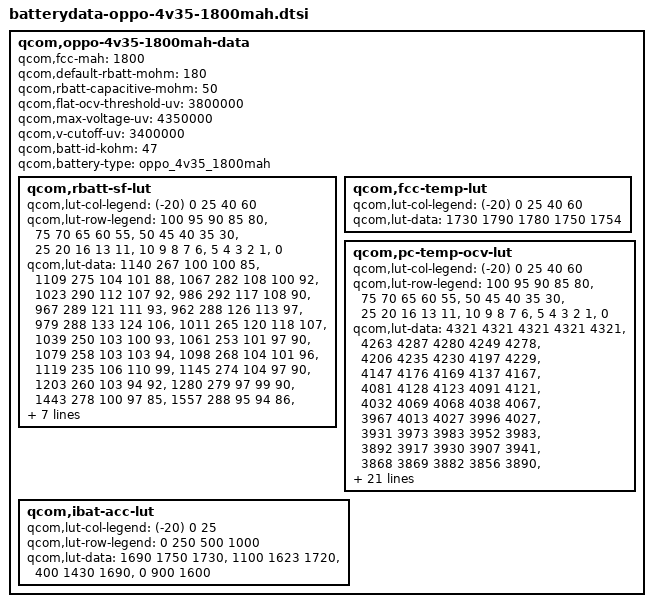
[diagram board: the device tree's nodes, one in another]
/* Copyright (c) 2013, The Linux Foundation. All rights reserved.
 *
 * This program is free software; you can redistribute it and/or modify
 * it under the terms of the GNU General Public License version 2 and
 * only version 2 as published by the Free Software Foundation.
 *
 * This program is distributed in the hope that it will be useful,
 * but WITHOUT ANY WARRANTY; without even the implied warranty of
 * MERCHANTABILITY or FITNESS FOR A PARTICULAR PURPOSE.  See the
 * GNU General Public License for more details.
 */

qcom,oppo-4v35-1800mah-data {
	qcom,fcc-mah = <1800>;
	qcom,default-rbatt-mohm = <180>;
	qcom,rbatt-capacitive-mohm = <50>;
	qcom,flat-ocv-threshold-uv = <3800000>;
	qcom,max-voltage-uv = <4350000>;
	qcom,v-cutoff-uv = <3400000>;
	//qcom,chg-term-ua = <100000>;
	qcom,batt-id-kohm = <47>;
	qcom,battery-type = "oppo_4v35_1800mah";

	qcom,rbatt-sf-lut {
		qcom,lut-col-legend = <(-20) 0 25 40 60>;
		qcom,lut-row-legend = <100 95 90 85 80>,
				<75 70 65 60 55>,
				<50 45 40 35 30>,
				<25 20 16 13 11>,
				<10 9 8 7 6>,
				<5 4 3 2 1>,
				<0>;
		qcom,lut-data = <1140 267 100 100 85>,
			   	<1109 275 104 101 88>,
			   	<1067 282 108 100 92>,
			   	<1023 290 112 107 92>,
			   	<986 292 117 108 90>,
			   	<967 289 121 111 93>,
			   	<962 288 126 113 97>,
			   	<979 288 133 124 106>,
			   	<1011 265 120 118 107>,
			   	<1039 250 103 100 93>,
			   	<1061 253 101 97 90>,
			   	<1079 258 103 103 94>,
			   	<1098 268 104 101 96>,
			   	<1119 235 106 110 99>,
			   	<1145 274 104 97 90>,
			   	<1203 260 103 94 92>,
			   	<1280 279 97 99 90>,
			   	<1443 278 100 97 85>,
			   	<1557 288 95 94 86>,
			   	<1661 288 96 99 96>,
			   	<1772 297 100 106 97>,
			   	<1828 303 106 104 97>,
			   	<1883 318 110 114 103>,
			   	<1939 343 115 108 101>,
			   	<1994 382 113 110 97>,
			   	<2000 439 111 110 100>,	
			   	<2106 535 121 113 105>,
			   	<2217 754 135 125 117>,
			  	<2772 1135 171 149 151>,
			   	<5550 1383 858 571 651>,
			   	<135251 124940 59087 49820 29672>;
	};

	qcom,fcc-temp-lut {
		qcom,lut-col-legend = <(-20) 0 25 40 60>;
		qcom,lut-data = <1730 1790 1780 1750 1754>;
	};

	qcom,pc-temp-ocv-lut {
		qcom,lut-col-legend = <(-20) 0 25 40 60>;
		qcom,lut-row-legend = <100 95 90 85 80>,
				<75 70 65 60 55>,
				<50 45 40 35 30>,
				<25 20 16 13 11>,
				<10 9 8 7 6>,
				<5 4 3 2 1>,
				<0>;
		//qcom,lut-data = <4342 4350 4341 4311 4337>,
		qcom,lut-data = <4321 4321 4321 4321 4321>,
			   	<4263 4287 4280 4249 4278>,
			   	<4206 4235 4230 4197 4229>,
			   	<4147 4176 4169 4137 4167>,
			   	<4081 4128 4123 4091 4121>,
			   	<4032 4069 4068 4038 4067>,
			   	<3967 4013 4027 3996 4027>,
			   	<3931 3973 3983 3952 3983>,
			   	<3892 3917 3930 3907 3941>,
			   	<3868 3869 3882 3856 3890>,
			   	<3837 3844 3850 3828 3865>,
			   	<3816 3820 3830 3806 3840>,
			   	<3798 3802 3810 3785 3824>,
			   	<3776 3790 3797 3775 3806>,
			   	<3760 3777 3781 3751 3782>,
			   	<3740 3770 3761 3730 3740>,
			   	<3725 3751 3742 3710 3710>,
			   	<3696 3712 3706 3699 3687>,
			   	<3663 3699 3691 3680 3671>,
			   	<3620 3663 3674 3672 3662>,
			   	<3601 3656 3671 3669 3659>,
			  	<3580 3649 3667 3666 3656>,
			  	<3560 3640 3660 3658 3649>,
			   	<3530 3629 3650 3650 3630>,
			   	<3500 3610 3624 3624 3607>,
			   	<3480 3577 3584 3585 3567>,
			   	<3460 3528 3531 3534 3516>,
			   	<3410 3463 3483 3465 3467>,
			   	<3350 3385 3354 3348 3338>,
			   	<3150 3175 3177 3162 3176>,
				<3000 3000 3000 3000 3000>;
	};
/*
	qcom,ibat-acc-lut {
		qcom,lut-col-legend = <(-20) 0 25>;
		qcom,lut-row-legend = <0 250 500 1000>;
		qcom,lut-data = <1740 1800 1780>,
				<1100 1623 1770>,
				<400 1430 1740>,
				<0 1130 1690>;
	};
*/
	qcom,ibat-acc-lut {
		qcom,lut-col-legend = <(-20) 0 25>;
		qcom,lut-row-legend = <0 250 500 1000>;
		qcom,lut-data = <1690 1750 1730>,
				<1100 1623 1720>,
				<400 1430 1690>,
				<0 900 1600>;
	};

};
